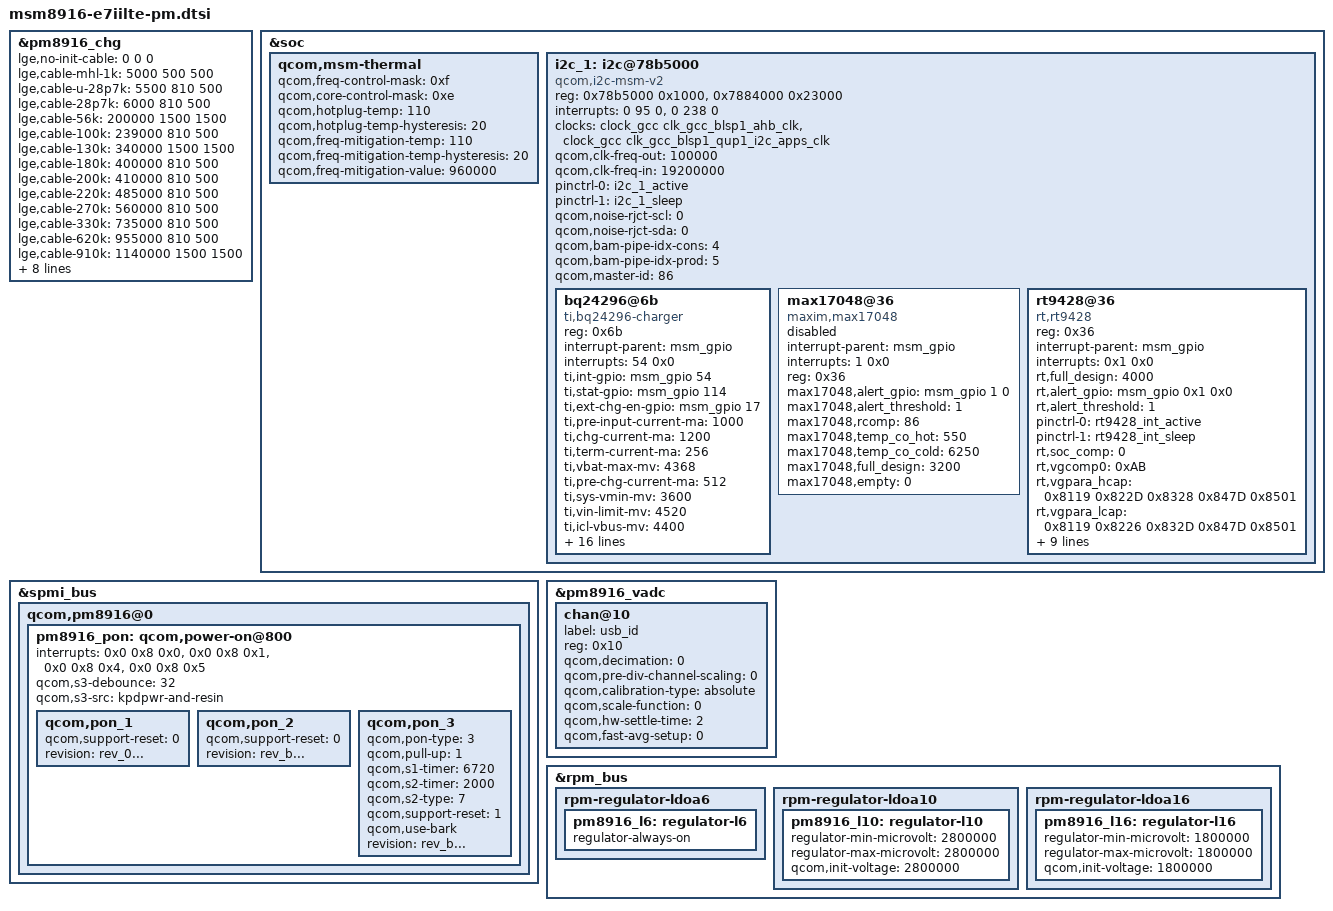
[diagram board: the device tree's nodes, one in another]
/* Copyright (c) 2012, Code Aurora Forum. All rights reserved.
 *
 * This program is free software; you can redistribute it and/or modify
* it under the terms of the GNU General Public License version 2 and
* only version 2 as published by the Free Software Foundation.
*
* This program is distributed in the hope that it will be useful,
* but WITHOUT ANY WARRANTY; without even the implied warranty of
* MERCHANTABILITY or FITNESS FOR A PARTICULAR PURPOSE.  See the
* GNU General Public License for more details.
*/

&pm8916_chg {
	status = "ok";

	lge,no-init-cable = <0 0 0>;
	lge,cable-mhl-1k = <5000 500 500>;
	lge,cable-u-28p7k = <5500 810 500>;
	lge,cable-28p7k = <6000 810 500>;
	lge,cable-56k = <200000 1500 1500>;
	lge,cable-100k = <239000 810 500>;
	lge,cable-130k = <340000 1500 1500>;
	lge,cable-180k = <400000 810 500>;
	lge,cable-200k = <410000 810 500>;
	lge,cable-220k = <485000 810 500>;
	lge,cable-270k = <560000 810 500>;
	lge,cable-330k = <735000 810 500>;
	lge,cable-620k = <955000 810 500>;
	lge,cable-910k = <1140000 1500 1500>;
	lge,cable-none = <1900000 810  500>;

	qcom,vddmax-mv = <4350>;
	qcom,vddsafe-mv = <4380>;
	qcom,vinmin-mv = <4470>;
	qcom,tchg-mins = <480>;
	qcom,btc-disabled = <1>;
	qcom,resume-soc = <98>;
	qcom,disable-vbatdet-based-recharge;
};

&soc {
	qcom,msm-thermal {
		qcom,freq-control-mask = <0xf>;
		qcom,core-control-mask = <0xe>;
		qcom,hotplug-temp = <110>;
		qcom,hotplug-temp-hysteresis = <20>;
		qcom,freq-mitigation-temp = <110>;
		qcom,freq-mitigation-temp-hysteresis = <20>;
		qcom,freq-mitigation-value = <960000>;
		};

	i2c_1: i2c@78b5000 { /* BLSP1 QUP1 */
		compatible = "qcom,i2c-msm-v2";
		#address-cells = <1>;
		#size-cells = <0>;
		reg-names = "qup_phys_addr", "bam_phys_addr";
		reg = <0x78b5000 0x1000>,
		<0x7884000 0x23000>;
		interrupt-names = "qup_irq", "bam_irq";
		interrupts = <0 95 0>, <0 238 0>;
		clocks = <&clock_gcc clk_gcc_blsp1_ahb_clk>,
		<&clock_gcc clk_gcc_blsp1_qup1_i2c_apps_clk>;
		clock-names = "iface_clk", "core_clk";
		qcom,clk-freq-out = <100000>;
		qcom,clk-freq-in  = <19200000>;
		pinctrl-names = "i2c_active", "i2c_sleep";
		pinctrl-0 = <&i2c_1_active>;
		pinctrl-1 = <&i2c_1_sleep>;
		qcom,noise-rjct-scl = <0>;
		qcom,noise-rjct-sda = <0>;
		qcom,bam-pipe-idx-cons = <4>;
		qcom,bam-pipe-idx-prod = <5>;
		qcom,master-id = <86>;
	};
	
};

&spmi_bus {
qcom,pm8916@0 {
	/delete-node/ qcom,leds@a100;

	pm8916_pon: qcom,power-on@800 {
			status = "ok";
			interrupts = <0x0 0x8 0x0>,
				     <0x0 0x8 0x1>,
				     <0x0 0x8 0x4>,
				     <0x0 0x8 0x5>;
			interrupt-names = "kpdpwr", "resin",
					"resin-bark", "kpdpwr-resin-bark";
			qcom,s3-debounce = <32>;
			qcom,s3-src = "kpdpwr-and-resin";

			qcom,pon_1 {
				status = "ok";
				qcom,support-reset = <0>;
				revision = "rev_0...";
			};
			qcom,pon_2 {
				status = "ok";
				qcom,support-reset = <0>;
				revision = "rev_b...";
			};
			qcom,pon_3 {
				status = "ok";
				qcom,pon-type = <3>;
				qcom,pull-up = <1>;
				qcom,s1-timer = <6720>;
				qcom,s2-timer = <2000>;
				qcom,s2-type = <7>;
				qcom,support-reset = <1>;
				qcom,use-bark;
				revision = "rev_b...";
			};
		};
	};
};

&pm8916_vadc {
	chan@10 {
		label = "usb_id";
		reg = <0x10>;
		qcom,decimation = <0>;
		qcom,pre-div-channel-scaling = <0>;
		qcom,calibration-type = "absolute";
		qcom,scale-function = <0>;
		qcom,hw-settle-time = <2>;
		qcom,fast-avg-setup = <0>;
	};
};

&i2c_1 {
	bq24296@6b {
		status = "ok";
		compatible = "ti,bq24296-charger";
		reg = <0x6b>;
		interrupt-parent = <&msm_gpio>;
		interrupts = <54 0x0>;
		ti,int-gpio = <&msm_gpio 54 0>;
		ti,stat-gpio = <&msm_gpio 114 0>;
		ti,ext-chg-en-gpio = <&msm_gpio 17 0>;
		ti,pre-input-current-ma = <1000>;
		ti,chg-current-ma = <1200>;
		ti,term-current-ma = <256>;
		ti,vbat-max-mv = <4368>;
		ti,pre-chg-current-ma = <512>;
		ti,sys-vmin-mv = <3600>;
		ti,vin-limit-mv = <4520>;
		ti,icl-vbus-mv = <4400>;

		lge,no-init-cable = <0 0 0>;
		lge,cable-mhl-1k = <5000 500 500>;
		lge,cable-u-28p7k = <5500 1500 500>;
		lge,cable-28p7k = <6000 1200 500>;
		lge,cable-56k = <178000 1500 1500>;
		lge,cable-100k = <178500 2000 500>;
		lge,cable-130k = <340000 500 500>;
		lge,cable-180k = <400000 1500 500>;
		lge,cable-200k = <410000 1500 500>;
		lge,cable-220k = <485000 1500 500>;
		lge,cable-270k = <560000 1500 500>;
		lge,cable-330k = <735000 1500 500>;
		lge,cable-620k = <955000 1500 500>;
		lge,cable-910k = <1200000 1500 1500>;
		lge,cable-none = <1900000 1500	500>;

		qcom,bq24296-vadc = <&pm8916_vadc>;
	};

	max17048@36 {
		compatible = "maxim,max17048";
		status = "disabled";
		interrupt-parent = <&msm_gpio>;
		interrupts = <1 0x0>;
		reg = <0x36>;
		max17048,alert_gpio = <&msm_gpio 1 0>;
		max17048,alert_threshold = <1>;
		max17048,rcomp = <86>;
		max17048,temp_co_hot = <550>;
		max17048,temp_co_cold = <6250>;
		max17048,full_design = <3200>;
		max17048,empty = <0>;     /* 3.4 Cut-off 0.0%  */
	};

	rt9428@36 {
		compatible = "rt,rt9428";
		status = "ok";
		reg = <0x36>;
		interrupt-parent = <&msm_gpio>;
		interrupts = <0x1 0x0>;
		rt,full_design= <4000>;
		rt,alert_gpio = <&msm_gpio 0x1 0x0>;
		rt,alert_threshold = <1>;
		/* Pins config setting */
		pinctrl-names = "default", "sleep";
		pinctrl-0 = <&rt9428_int_active>;
		pinctrl-1 = <&rt9428_int_sleep>;
		rt,soc_comp = <0>;
		rt,vgcomp0 = <0xAB>;
		rt,vgpara_hcap = <0x8119 0x822D 0x8328 0x847D 0x8501>;
		rt,vgpara_lcap = <0x8119 0x8226 0x832D 0x847D 0x8501>;
		rt,r1_gain_hcap = < 0 75  0 25  0 75>;
		rt,r2_gain_hcap = < 1 135 0 85 	1 135>;
		rt,r3_gain_hcap = < 1 100 0 225 1 100>;
		rt,r4_gain_hcap = < 1 325 0 0 	1 325>;
		rt,r1_gain_lcap = < 0 75  0 25  0 75>;
		rt,r2_gain_lcap = < 1 90  0 50 	1 90>;
		rt,r3_gain_lcap = < 1 125 0 225 1 125>;
		rt,r4_gain_lcap = < 1 325 0 0 	1 325>;
		rt,temp_base = <5 5 25 45>;
	};
};

&rpm_bus {
	rpm-regulator-ldoa6 {
		status = "okay";
		pm8916_l6: regulator-l6 {
			regulator-always-on;
			status = "okay";
		};
	};

	rpm-regulator-ldoa10 {
		status = "okay";
		pm8916_l10: regulator-l10 {
			regulator-min-microvolt = <2800000>;
			regulator-max-microvolt = <2800000>;
			qcom,init-voltage = <2800000>;
			//regulator-always-on;
			status = "okay";
		};
	};

	rpm-regulator-ldoa16 {
		status = "okay";
		pm8916_l16: regulator-l16 {
			regulator-min-microvolt = <1800000>;
			regulator-max-microvolt = <1800000>;
			qcom,init-voltage = <1800000>;
			status = "okay";
		};
	};
};
